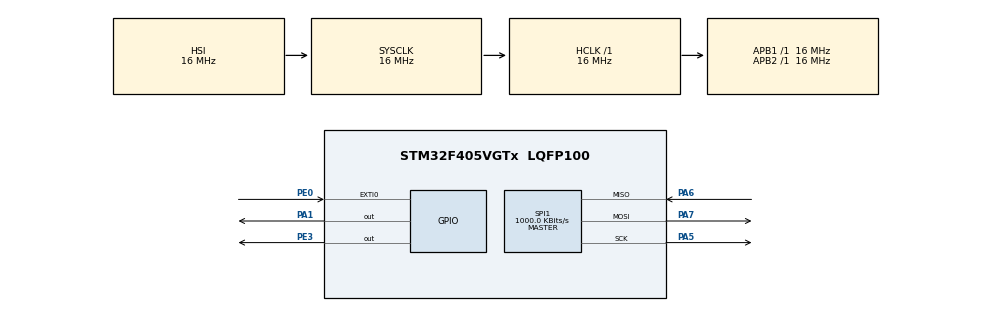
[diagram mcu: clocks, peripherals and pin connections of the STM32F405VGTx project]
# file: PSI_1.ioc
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Mcu.Family=STM32F4
Mcu.Name=STM32F405VGTx
Mcu.Package=LQFP100
NVIC.EXTI0_IRQn=true\:0\:0\:false\:false\:true\:true\:true
NVIC.PriorityGroup=NVIC_PRIORITYGROUP_4
PA1.Signal=GPIO_Output
PA5.Mode=Full_Duplex_Master
PA5.Signal=SPI1_SCK
PA6.Mode=Full_Duplex_Master
PA6.Signal=SPI1_MISO
PA7.Mode=Full_Duplex_Master
PA7.Signal=SPI1_MOSI
PE0.Signal=GPXTI0
PE3.GPIO_ModeDefaultOutputPP=GPIO_MODE_OUTPUT_PP
PE3.GPIO_PuPd=GPIO_NOPULL
PE3.GPIO_Speed=GPIO_SPEED_FREQ_LOW
PE3.PinState=GPIO_PIN_RESET
PE3.Signal=GPIO_Output
ProjectManager.HeapSize=0x200
ProjectManager.StackSize=0x400
ProjectManager.TargetToolchain=MDK-ARM V5.27
RCC.AHBFreq_Value=16000000
RCC.APB1Freq_Value=16000000
RCC.APB2Freq_Value=16000000
RCC.CortexFreq_Value=16000000
RCC.HSE_VALUE=25000000
RCC.HSI_VALUE=16000000
RCC.LSE_VALUE=32768
RCC.SYSCLKFreq_VALUE=16000000
RCC.VCOOutputFreq_Value=192000000
SPI1.BaudRatePrescaler=SPI_BAUDRATEPRESCALER_16
SPI1.CalculateBaudRate=1000.0 KBits/s
SPI1.Direction=SPI_DIRECTION_2LINES
SPI1.Mode=SPI_MODE_MASTER
SPI1.VirtualType=VM_MASTER
board=custom

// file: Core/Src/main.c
/* USER CODE BEGIN Header */
/**
  ******************************************************************************
  * @file           : main.c
  * @brief          : Main program body
  ******************************************************************************
  * @attention
  *
  * <h2><center>&copy; Copyright (c) 2020 STMicroelectronics.
  * All rights reserved.</center></h2>
  *
  * This software component is licensed by ST under BSD 3-Clause license,
  * the "License"; You may not use this file except in compliance with the
  * License. You may obtain a copy of the License at:
  *                        opensource.org/licenses/BSD-3-Clause
  *
  ******************************************************************************
  */
/* USER CODE END Header */
#include "main.h"
#include "spi.h"
#include "gpio.h"

void SystemClock_Config(void);

/* USER CODE BEGIN 0 */
uint8_t spiTxBuf[2], spiRxBuf[2];
/* USER CODE END 0 */

int main(void)
{

  /* MCU Configuration--------------------------------------------------------*/

  /* Reset of all peripherals, Initializes the Flash interface and the Systick. */
  HAL_Init();

  /* Configure the system clock */
  SystemClock_Config();

  /* Initialize all configured peripherals */
  MX_GPIO_Init();
  MX_SPI1_Init();
  /* USER CODE BEGIN 2 */
	//***********SPI Transmit*****************
	//1.Bring slave select to low
	HAL_GPIO_WritePin(GPIOE, GPIO_PIN_3,GPIO_PIN_RESET);
	//2. Transmit register +data
	spiTxBuf[0]=0x20;
	spiTxBuf[0]=0x11;
	HAL_SPI_Transmit(&hspi1,spiTxBuf,2,50);
	//3. bring tje slave select high
	HAL_GPIO_WritePin(GPIOE, GPIO_PIN_3,GPIO_PIN_SET);

	//***********SPI Receive*****************
	//1.Bring slave select low
	HAL_GPIO_WritePin(GPIOE, GPIO_PIN_3,GPIO_PIN_RESET);
	//2.Transmit register + 0x80 (to set MSB bit to high, read mode)
	spiTxBuf[0] =0x20|0x80;
	HAL_SPI_Transmit(&hspi1,spiTxBuf,1,50);
	//3.Receive data
	HAL_SPI_Receive(&hspi1,spiRxBuf,1,50);
	//4.Bring slave select high
	HAL_GPIO_WritePin(GPIOE, GPIO_PIN_3, GPIO_PIN_SET);
  /* USER CODE END 2 */

  /* Infinite loop */
  while (1)
  {

  }
}

void SystemClock_Config(void)
{
  RCC_OscInitTypeDef RCC_OscInitStruct = {0};
  RCC_ClkInitTypeDef RCC_ClkInitStruct = {0};

  /** Configure the main internal regulator output voltage
  */
  __HAL_RCC_PWR_CLK_ENABLE();
  __HAL_PWR_VOLTAGESCALING_CONFIG(PWR_REGULATOR_VOLTAGE_SCALE1);
  /** Initializes the RCC Oscillators according to the specified parameters
  * in the RCC_OscInitTypeDef structure.
  */
  RCC_OscInitStruct.OscillatorType = RCC_OSCILLATORTYPE_HSI;
  RCC_OscInitStruct.HSIState = RCC_HSI_ON;
  RCC_OscInitStruct.HSICalibrationValue = RCC_HSICALIBRATION_DEFAULT;
  RCC_OscInitStruct.PLL.PLLState = RCC_PLL_NONE;
  if (HAL_RCC_OscConfig(&RCC_OscInitStruct) != HAL_OK)
  {
    Error_Handler();
  }
  /** Initializes the CPU, AHB and APB buses clocks
  */
  RCC_ClkInitStruct.ClockType = RCC_CLOCKTYPE_HCLK|RCC_CLOCKTYPE_SYSCLK
                              |RCC_CLOCKTYPE_PCLK1|RCC_CLOCKTYPE_PCLK2;
  RCC_ClkInitStruct.SYSCLKSource = RCC_SYSCLKSOURCE_HSI;
  RCC_ClkInitStruct.AHBCLKDivider = RCC_SYSCLK_DIV1;
  RCC_ClkInitStruct.APB1CLKDivider = RCC_HCLK_DIV1;
  RCC_ClkInitStruct.APB2CLKDivider = RCC_HCLK_DIV1;

  if (HAL_RCC_ClockConfig(&RCC_ClkInitStruct, FLASH_LATENCY_0) != HAL_OK)
  {
    Error_Handler();
  }
}

void Error_Handler(void)
{
}

/************************ (C) COPYRIGHT STMicroelectronics *****END OF FILE****/
